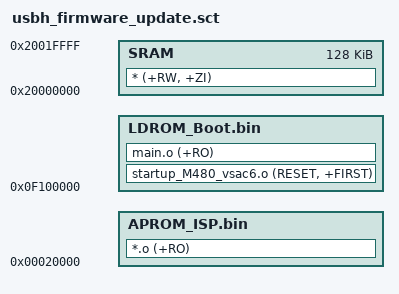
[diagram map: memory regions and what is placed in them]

LOAD_ROM_1  0xF100000
{
	LDROM_Boot.bin  0xF100000
	{
		startup_M480_vsac6.o (RESET, +FIRST)
		main.o (+RO)
	}

	SRAM  0x20000000 0x20000
	{
		* (+RW, +ZI)
	}
}

LOAD_ROM_2  0x20000
{
	APROM_ISP.bin  0x20000
	{
		*.o (+RO)
	}
}
